AUTOSAR XML (schema 4-2-2)
package /ComponentTypes
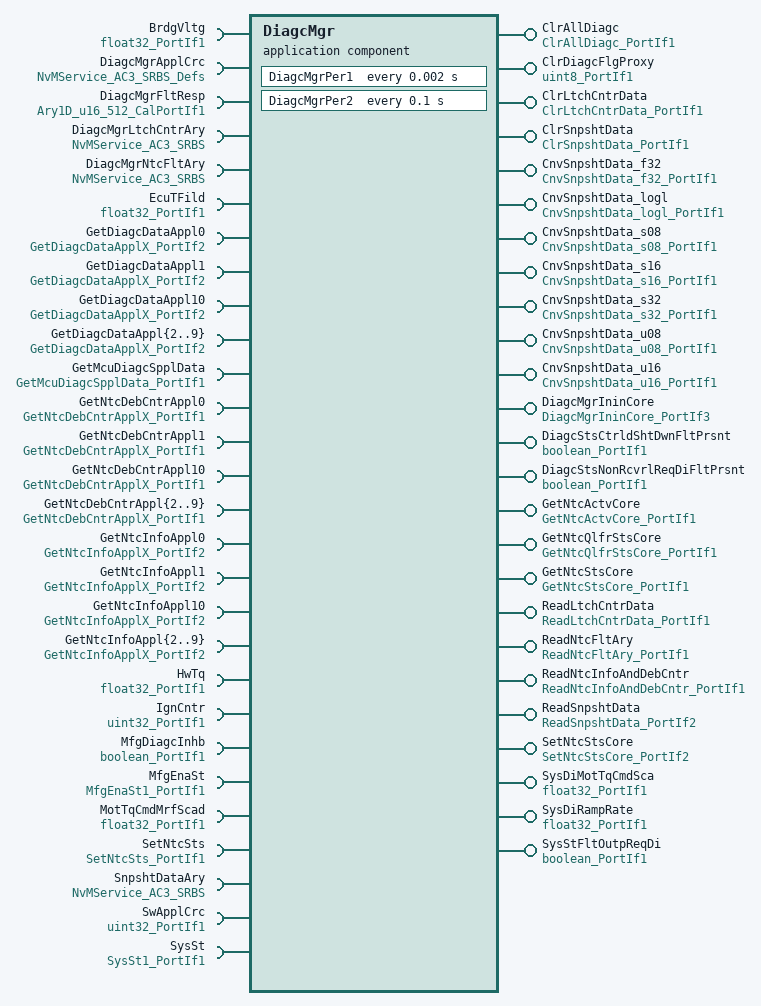
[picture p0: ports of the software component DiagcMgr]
  application sw component type DiagcMgr
    25 x provide port:
      ClrAllDiagc: server-com-spec{operation=Oper, queue-length=1}, provided-interface=ClrAllDiagc_PortIf1
      ClrDiagcFlgProxy: nonqueued-sender-com-spec{data-element=Val, init-value=0}, provided-interface=uint8_PortIf1
      ClrLtchCntrData: server-com-spec{operation=Oper, queue-length=1}, provided-interface=ClrLtchCntrData_PortIf1
      ClrSnpshtData: server-com-spec{operation=Oper, queue-length=1}, provided-interface=ClrSnpshtData_PortIf1
      CnvSnpshtData_f32: server-com-spec{operation=Oper, queue-length=1}, provided-interface=CnvSnpshtData_f32_PortIf1
      CnvSnpshtData_logl: server-com-spec{operation=Oper, queue-length=1}, provided-interface=CnvSnpshtData_logl_PortIf1
      CnvSnpshtData_s08: server-com-spec{operation=Oper, queue-length=1}, provided-interface=CnvSnpshtData_s08_PortIf1
      CnvSnpshtData_s16: server-com-spec{operation=Oper, queue-length=1}, provided-interface=CnvSnpshtData_s16_PortIf1
      CnvSnpshtData_s32: server-com-spec{operation=Oper, queue-length=1}, provided-interface=CnvSnpshtData_s32_PortIf1
      CnvSnpshtData_u08: server-com-spec{operation=Oper, queue-length=1}, provided-interface=CnvSnpshtData_u08_PortIf1
      CnvSnpshtData_u16: server-com-spec{operation=Oper, queue-length=1}, provided-interface=CnvSnpshtData_u16_PortIf1
      DiagcMgrIninCore: server-com-spec{operation=Oper, queue-length=1}, provided-interface=DiagcMgrIninCore_PortIf3
      DiagcStsCtrldShtDwnFltPrsnt: nonqueued-sender-com-spec{data-element=Logl, init-value=0}, provided-interface=boolean_PortIf1
      DiagcStsNonRcvrlReqDiFltPrsnt: nonqueued-sender-com-spec{data-element=Logl, init-value=0}, provided-interface=boolean_PortIf1
      GetNtcActvCore: server-com-spec{operation=Oper, queue-length=1}, provided-interface=GetNtcActvCore_PortIf1
      GetNtcQlfrStsCore: server-com-spec{operation=Oper, queue-length=1}, provided-interface=GetNtcQlfrStsCore_PortIf1
      GetNtcStsCore: server-com-spec{operation=Oper, queue-length=1}, provided-interface=GetNtcStsCore_PortIf1
      ReadLtchCntrData: server-com-spec{operation=Oper, queue-length=1}, provided-interface=ReadLtchCntrData_PortIf1
      ReadNtcFltAry: server-com-spec{operation=Oper, queue-length=1}, provided-interface=ReadNtcFltAry_PortIf1
      ReadNtcInfoAndDebCntr: server-com-spec{operation=Oper, queue-length=1}, provided-interface=ReadNtcInfoAndDebCntr_PortIf1
      ReadSnpshtData: server-com-spec{operation=Oper, queue-length=1}, provided-interface=ReadSnpshtData_PortIf2
      SetNtcStsCore: server-com-spec{operation=Oper, queue-length=1}, provided-interface=SetNtcStsCore_PortIf2
      SysDiMotTqCmdSca: nonqueued-sender-com-spec{data-element=Val, init-value=1}, provided-interface=float32_PortIf1
      SysDiRampRate: nonqueued-sender-com-spec{data-element=Val, init-value=0.1}, provided-interface=float32_PortIf1
      SysStFltOutpReqDi: nonqueued-sender-com-spec{data-element=Logl, init-value=0}, provided-interface=boolean_PortIf1
    49 x require port:
      BrdgVltg: nonqueued-receiver-com-spec{data-element=Val, filter=data-filter-type=ALWAYS, init-value=6}, required-interface=float32_PortIf1
      DiagcMgrApplCrc: required-com-specs=[EraseBlock, GetErrorStatus, InvalidateNvBlock, ReadBlock, RestoreBlockDefaults, SetRamBlockStatus, WriteBlock], required-interface=NvMService_AC3_SRBS_Defs
      DiagcMgrFltResp: parameter-require-com-spec{init-value=[0, 34560, 34560, 34560, 34560, 34560, 34560, 34560, 34560, 34560, 34560, 34560, 34560, 34560, 34560, 34560, 34560, 34560, 34560, 34560, 34560, 34560, 34560, 34560, 34560, 34560, 34560, 34560, 34560, 34560, 34560, 34560, 34560, 34560, 34560, 34560, 34560, 34560, 34560, 34560, 34560, 34560, 34560, 34560, 34560, 34560, 34560, 34560, 34560, 34560, 34560, 34560, 34560, 34560, 34560, 34560, 34560, 34560, 34560, 34560, 34560, 34560, 34560, 34560, 34560, 34560, 34560, 34560, 34560, 34560, 34560, 34560, 34560, 34560, 34560, 34560, 34560, 34560, 34560, 34560, 34560, 34560, 34560, 34560, 34560, 34560, 34560, 34560, 34560, 34560, 34560, 34560, 34560, 34560, 34560, 34560, 34560, 34560, 34560, 34560, 34560, 34560, 34560, 34560, 34560, 34560, 34560, 34560, 34560, 34560, 34560, 34560, 34560, 34560, 34560, 34560, 34560, 34560, 34560, 34560, 34560, 34560, 34560, 34560, 34560, 34560, 34560, 34560, 34560, 34560, 34560, 34560, 34560, 34560, 34560, 34560, 34560, 34560, 34560, 34560, 34560, 34560, 34560, 34560, 34560, 34560, 34560, 34560, 34560, 34560, 34560, 34560, 34560, 34560, 34560, 34560, 34560, 34560, 34560, 34560, 34560, 34560, 34560, 34560, 34560, 34560, 34560, 34560, 34560, 34560, 34560, 34560, 34560, 34560, 34560, 34560, 34560, 34560, 34560, 34560, 34560, 34560, 34560, 34560, 34560, 34560, 34560, 34560, 34560, 34560, 34560, 34560, 34560, 34560, 34560, 34560, 34560, 34560, 34560, 34560, 34560, 34560, 34560, 34560, 34560, 34560, 34560, 34560, 34560, 34560, 34560, 34560, 34560, 34560, 34560, 34560, 34560, 34560, 34560, 34560, 34560, 34560, 34560, 34560, 34560, 34560, 34560, 34560, 34560, 34560, 34560, 34560, 34560, 34560, 34560, 34560, 34560, 34560, 34560, 34560, 34560, 34560, 34560, 34560, 34560, 34560, 34560, 34560, 34560, 34560, 34560, 34560, 34560, 34560, 34560, 34560, 34560, 34560, 34560, 34560, 34560, 34560, 34560, 34560, 34560, 34560, 34560, 34560, 34560, 34560, 34560, 34560, 34560, 34560, 34560, 34560, 34560, 34560, 34560, 34560, 34560, 34560, 34560, 34560, 34560, 34560, 34560, 34560, 34560, 34560, 34560, 34560, 34560, 34560, 34560, 34560, 34560, 34560, 34560, 34560, 34560, 34560, 34560, 34560, 34560, 34560, 34560, 34560, 34560, 34560, 34560, 34560, 34560, 34560, 34560, 34560, 34560, 34560, 34560, 34560, 34560, 34560, 34560, 34560, 34560, 34560, 34560, 34560, 34560, 34560, 34560, 34560, 34560, 34560, 34560, 34560, 34560, 34560, 34560, 34560, 34560, 34560, 34560, 34560, 34560, 34560, 34560, 34560, 34560, 34560, 34560, 34560, 34560, 34560, 34560, 34560, 34560, 34560, 34560, 34560, 34560, 34560, 34560, 34560, 34560, 34560, 34560, 34560, 34560, 34560, 34560, 34560, 34560, 34560, 34560, 34560, 34560, 34560, 34560, 34560, 34560, 34560, 34560, 34560, 34560, 34560, 34560, 34560, 34560, 34560, 34560, 34560, 34560, 34560, 34560, 34560, 34560, 34560, 34560, 34560, 34560, 34560, 34560, 34560, 34560, 34560, 34560, 34560, 34560, 34560, 34560, 34560, 34560, 34560, 34560, 34560, 34560, 34560, 34560, 34560, 34560, 34560, 34560, 34560, 34560, 34560, 34560, 34560, 34560, 34560, 34560, 34560, 34560, 34560, 34560, 34560, 34560, 34560, 34560, 34560, 34560, 34560, 34560, 34560, 34560, 34560, 34560, 34560, 34560, 34560, 34560, 34560, 34560, 34560, 34560, 34560, 34560, 34560, 34560, 34560, 34560, 34560, 34560, 34560, 34560, 34560, 34560, 34560, 34560, 34560, 34560, 34560, 34560, 34560, 34560, 34560, 34560, 34560, 34560, 34560, 34560, 34560, 34560, 34560, 34560, 34560, 34560, 34560, 34560, 34560, 34560, 34560, 34560, 34560, 34560, 34560, 34560, 34560, 34560, 34560, 34560, 34560, 34560, 34560, 34560, 34560, 34560, 34560, 34560, 34560, 34560, 34560], parameter=Ary1D}, required-interface=Ary1D_u16_512_CalPortIf1
      DiagcMgrLtchCntrAry: required-com-specs=[EraseBlock, GetErrorStatus, InvalidateNvBlock, ReadBlock, SetRamBlockStatus, WriteBlock], required-interface=NvMService_AC3_SRBS
      DiagcMgrNtcFltAry: required-com-specs=[EraseBlock, GetErrorStatus, InvalidateNvBlock, ReadBlock, SetRamBlockStatus, WriteBlock], required-interface=NvMService_AC3_SRBS
      EcuTFild: nonqueued-receiver-com-spec{data-element=Val, filter=data-filter-type=ALWAYS, init-value=25}, required-interface=float32_PortIf1
      GetDiagcDataAppl0: client-com-spec=Oper, required-interface=GetDiagcDataApplX_PortIf2
      GetDiagcDataAppl1: client-com-spec=Oper, required-interface=GetDiagcDataApplX_PortIf2
      GetDiagcDataAppl10: client-com-spec=Oper, required-interface=GetDiagcDataApplX_PortIf2
      GetDiagcDataAppl{2..9}: client-com-spec=Oper, required-interface=GetDiagcDataApplX_PortIf2
      GetMcuDiagcSpplData: client-com-spec=Oper, required-interface=GetMcuDiagcSpplData_PortIf1
      GetNtcDebCntrAppl0: client-com-spec=Oper, required-interface=GetNtcDebCntrApplX_PortIf1
      GetNtcDebCntrAppl1: client-com-spec=Oper, required-interface=GetNtcDebCntrApplX_PortIf1
      GetNtcDebCntrAppl10: client-com-spec=Oper, required-interface=GetNtcDebCntrApplX_PortIf1
      GetNtcDebCntrAppl{2..9}: client-com-spec=Oper, required-interface=GetNtcDebCntrApplX_PortIf1
      GetNtcInfoAppl0: client-com-spec=Oper, required-interface=GetNtcInfoApplX_PortIf2
      GetNtcInfoAppl1: client-com-spec=Oper, required-interface=GetNtcInfoApplX_PortIf2
      GetNtcInfoAppl10: client-com-spec=Oper, required-interface=GetNtcInfoApplX_PortIf2
      GetNtcInfoAppl{2..9}: client-com-spec=Oper, required-interface=GetNtcInfoApplX_PortIf2
      HwTq: nonqueued-receiver-com-spec{data-element=Val, filter=data-filter-type=ALWAYS, init-value=0}, required-interface=float32_PortIf1
      IgnCntr: nonqueued-receiver-com-spec{data-element=Val, filter=data-filter-type=ALWAYS, init-value=0}, required-interface=uint32_PortIf1
      MfgDiagcInhb: nonqueued-receiver-com-spec{data-element=Logl, filter=data-filter-type=ALWAYS, init-value=0}, required-interface=boolean_PortIf1
      MfgEnaSt: nonqueued-receiver-com-spec{data-element=Val, filter=data-filter-type=ALWAYS, init-value=0}, required-interface=MfgEnaSt1_PortIf1
      MotTqCmdMrfScad: nonqueued-receiver-com-spec{data-element=Val, filter=data-filter-type=ALWAYS, init-value=0}, required-interface=float32_PortIf1
      SetNtcSts: client-com-spec=Oper, required-interface=SetNtcSts_PortIf1
      SnpshtDataAry: required-com-specs=[EraseBlock, GetErrorStatus, InvalidateNvBlock, ReadBlock, SetRamBlockStatus, WriteBlock], required-interface=NvMService_AC3_SRBS
      SwApplCrc: nonqueued-receiver-com-spec{data-element=Val, filter=data-filter-type=ALWAYS, init-value=0}, required-interface=uint32_PortIf1
      SysSt: nonqueued-receiver-com-spec{data-element=Val, filter=data-filter-type=ALWAYS, init-value=3}, required-interface=SysSt1_PortIf1
    behavior DiagcMgr_InternalBehavior
      exclusive area DiagcMgrExclusiveArea
      ar-typed-per-instance-memorys:
        7 x data:
          ClrDiagcFlg: sw-calibration-access=READ-ONLY, type=uint8
          DiagcMgrApplCrc: sw-calibration-access=READ-ONLY, type=uint32
          DiagcMgrLtchCntrAry: sw-calibration-access=READ-ONLY, type=Ary1D_u08_20
          DiagcMgrNtcFltAry: sw-calibration-access=READ-ONLY, type=Ary1D_NtcFltInfoRec2_20
          DtcEnaSts: sw-calibration-access=READ-ONLY, type=uint16
          DtcIdxPrevSts: type=Ary1D_u08_DiagcMgr1
          PrevClrDtcFlg: sw-calibration-access=READ-ONLY, type=uint8
      11 x operation invoked event:
        OIT_ClrAllDiagc_Oper_ClrAllDiagc_Oper: start-on-event=ClrAllDiagc_Oper, operation=ClrAllDiagc.Oper
        OIT_ClrLtchCntrData_Oper_ClrLtchCntrData_Oper: start-on-event=ClrLtchCntrData_Oper, operation=ClrLtchCntrData.Oper
        OIT_ClrSnpshtData_Oper_ClrSnpshtData_Oper: start-on-event=ClrSnpshtData_Oper, operation=ClrSnpshtData.Oper
        OIT_CnvSnpshtData_f32_Oper_CnvSnpshtData_f32_Oper: start-on-event=CnvSnpshtData_f32_Oper, operation=CnvSnpshtData_f32.Oper
        OIT_CnvSnpshtData_logl_Oper_CnvSnpshtData_logl_Oper: start-on-event=CnvSnpshtData_logl_Oper, operation=CnvSnpshtData_logl.Oper
        OIT_CnvSnpshtData_s08_Oper_CnvSnpshtData_s08_Oper: start-on-event=CnvSnpshtData_s08_Oper, operation=CnvSnpshtData_s08.Oper
        OIT_CnvSnpshtData_s16_Oper_CnvSnpshtData_s16_Oper: start-on-event=CnvSnpshtData_s16_Oper, operation=CnvSnpshtData_s16.Oper
        OIT_CnvSnpshtData_s32_Oper_CnvSnpshtData_s32_Oper: start-on-event=CnvSnpshtData_s32_Oper, operation=CnvSnpshtData_s32.Oper
        OIT_CnvSnpshtData_u08_Oper_CnvSnpshtData_u08_Oper: start-on-event=CnvSnpshtData_u08_Oper, operation=CnvSnpshtData_u08.Oper
        OIT_CnvSnpshtData_u16_Oper_CnvSnpshtData_u16_Oper: start-on-event=CnvSnpshtData_u16_Oper, operation=CnvSnpshtData_u16.Oper
        OIT_DiagcMgrIninCore_Oper_DiagcMgrIninCore_Oper: start-on-event=DiagcMgrIninCore_Oper, operation=DiagcMgrIninCore.Oper
      init event DiagcMgr_InitEvent: start-on-event=DiagcMgrInit1
      timing event TMT_DiagcMgrPer1: start-on-event=DiagcMgrPer1, period=0.002
      timing event TMT_DiagcMgrPer2: start-on-event=DiagcMgrPer2, period=0.1
      8 x operation invoked event:
        OIT_GetNtcActvCore_Oper_GetNtcActvCore_Oper: start-on-event=GetNtcActvCore_Oper, operation=GetNtcActvCore.Oper
        OIT_GetNtcQlfrStsCore_Oper_GetNtcQlfrStsCore_Oper: start-on-event=GetNtcQlfrStsCore_Oper, operation=GetNtcQlfrStsCore.Oper
        OIT_GetNtcStsCore_Oper_GetNtcStsCore_Oper: start-on-event=GetNtcStsCore_Oper, operation=GetNtcStsCore.Oper
        OIT_ReadLtchCntrData_Oper_ReadLtchCntrData_Oper: start-on-event=ReadLtchCntrData_Oper, operation=ReadLtchCntrData.Oper
        OIT_ReadNtcFltAry_Oper_ReadNtcFltAry_Oper: start-on-event=ReadNtcFltAry_Oper, operation=ReadNtcFltAry.Oper
        OIT_ReadNtcInfoAndDebCntr_Oper_ReadNtcInfoAndDebCntr_Oper: start-on-event=ReadNtcInfoAndDebCntr_Oper, operation=ReadNtcInfoAndDebCntr.Oper
        OIT_ReadSnpshtData_Oper_ReadSnpshtData_Oper: start-on-event=ReadSnpshtData_Oper, operation=ReadSnpshtData.Oper
        OIT_SetNtcStsCore_Oper_SetNtcStsCore_Oper: start-on-event=SetNtcStsCore_Oper, operation=SetNtcStsCore.Oper
      22 x runnable:
        ClrAllDiagc_Oper: can-be-invoked-concurrently=true
          data-send-points:
            access SEND_ClrDiagcFlg_Val: accessed-variable=ClrDiagcFlgProxy.Val
        ClrLtchCntrData_Oper
          sync call SC_DiagcMgrLtchCntrAry_SetRamBlockStatus: operation=DiagcMgrLtchCntrAry.SetRamBlockStatus, timeout=0
        ClrSnpshtData_Oper
          sync call SC_SnpshtDataAry_SetRamBlockStatus: operation=SnpshtDataAry.SetRamBlockStatus, timeout=0
        CnvSnpshtData_f32_Oper: can-be-invoked-concurrently=true
        CnvSnpshtData_logl_Oper: can-be-invoked-concurrently=true
        CnvSnpshtData_s08_Oper: can-be-invoked-concurrently=true
        CnvSnpshtData_s16_Oper: can-be-invoked-concurrently=true
        CnvSnpshtData_s32_Oper: can-be-invoked-concurrently=true
        CnvSnpshtData_u08_Oper: can-be-invoked-concurrently=true
        CnvSnpshtData_u16_Oper: can-be-invoked-concurrently=true
        DiagcMgrIninCore_Oper: can-be-invoked-concurrently=true
        DiagcMgrInit1
          data-receive-point-by-arguments:
            access REC_SwApplCrc_Val: accessed-variable=SwApplCrc.Val
          sync call SC_DiagcMgrApplCrc_SetRamBlockStatus: operation=DiagcMgrApplCrc.SetRamBlockStatus, timeout=0
          sync call SC_SetNtcSts_Oper: operation=SetNtcSts.Oper, timeout=0
        DiagcMgrPer1
          data-send-points:
            5 x access:
              SEND_DiagcStsCtrldShtDwnFltPrsnt_Logl: accessed-variable=DiagcStsCtrldShtDwnFltPrsnt.Logl
              SEND_DiagcStsNonRcvrlReqDiFltPrsnt_Logl: accessed-variable=DiagcStsNonRcvrlReqDiFltPrsnt.Logl
              SEND_SysDiMotTqCmdSca_Val: accessed-variable=SysDiMotTqCmdSca.Val
              SEND_SysDiRampRate_Val: accessed-variable=SysDiRampRate.Val
              SEND_SysStFltOutpReqDi_Logl: accessed-variable=SysStFltOutpReqDi.Logl
          11 x sync call, all with timeout=0:
            SC_GetDiagcDataAppl0_Oper: operation=GetDiagcDataAppl0.Oper
            SC_GetDiagcDataAppl1_Oper: operation=GetDiagcDataAppl1.Oper
            SC_GetDiagcDataAppl10_Oper: operation=GetDiagcDataAppl10.Oper
            SC_GetDiagcDataAppl{2..9}_Oper: operation=GetDiagcDataAppl{2..9}.Oper
        DiagcMgrPer2
          11 x sync call, all with timeout=0:
            SC_GetNtcInfoAppl0_Oper: operation=GetNtcInfoAppl0.Oper
            SC_GetNtcInfoAppl1_Oper: operation=GetNtcInfoAppl1.Oper
            SC_GetNtcInfoAppl10_Oper: operation=GetNtcInfoAppl10.Oper
            SC_GetNtcInfoAppl{2..9}_Oper: operation=GetNtcInfoAppl{2..9}.Oper
        GetNtcActvCore_Oper: can-be-invoked-concurrently=true
          11 x sync call, all with timeout=0:
            SC_GetNtcInfoAppl0_Oper: operation=GetNtcInfoAppl0.Oper
            SC_GetNtcInfoAppl1_Oper: operation=GetNtcInfoAppl1.Oper
            SC_GetNtcInfoAppl10_Oper: operation=GetNtcInfoAppl10.Oper
            SC_GetNtcInfoAppl{2..9}_Oper: operation=GetNtcInfoAppl{2..9}.Oper
        GetNtcQlfrStsCore_Oper: can-be-invoked-concurrently=true
          11 x sync call, all with timeout=0:
            SC_GetNtcInfoAppl0_Oper: operation=GetNtcInfoAppl0.Oper
            SC_GetNtcInfoAppl1_Oper: operation=GetNtcInfoAppl1.Oper
            SC_GetNtcInfoAppl10_Oper: operation=GetNtcInfoAppl10.Oper
            SC_GetNtcInfoAppl{2..9}_Oper: operation=GetNtcInfoAppl{2..9}.Oper
        GetNtcStsCore_Oper: can-be-invoked-concurrently=true
          11 x sync call, all with timeout=0:
            SC_GetNtcInfoAppl0_Oper: operation=GetNtcInfoAppl0.Oper
            SC_GetNtcInfoAppl1_Oper: operation=GetNtcInfoAppl1.Oper
            SC_GetNtcInfoAppl10_Oper: operation=GetNtcInfoAppl10.Oper
            SC_GetNtcInfoAppl{2..9}_Oper: operation=GetNtcInfoAppl{2..9}.Oper
        ReadLtchCntrData_Oper
        ReadNtcFltAry_Oper: can-be-invoked-concurrently=true
          11 x sync call, all with timeout=0:
            SC_GetNtcInfoAppl0_Oper: operation=GetNtcInfoAppl0.Oper
            SC_GetNtcInfoAppl1_Oper: operation=GetNtcInfoAppl1.Oper
            SC_GetNtcInfoAppl10_Oper: operation=GetNtcInfoAppl10.Oper
            SC_GetNtcInfoAppl{2..9}_Oper: operation=GetNtcInfoAppl{2..9}.Oper
        ReadNtcInfoAndDebCntr_Oper: can-be-invoked-concurrently=true
          22 x sync call, all with timeout=0:
            SC_GetNtcDebCntrAppl0_Oper: operation=GetNtcDebCntrAppl0.Oper
            SC_GetNtcDebCntrAppl1_Oper: operation=GetNtcDebCntrAppl1.Oper
            SC_GetNtcDebCntrAppl10_Oper: operation=GetNtcDebCntrAppl10.Oper
            SC_GetNtcDebCntrAppl{2..9}_Oper: operation=GetNtcDebCntrAppl{2..9}.Oper
            SC_GetNtcInfoAppl0_Oper: operation=GetNtcInfoAppl0.Oper
            SC_GetNtcInfoAppl1_Oper: operation=GetNtcInfoAppl1.Oper
            SC_GetNtcInfoAppl10_Oper: operation=GetNtcInfoAppl10.Oper
            SC_GetNtcInfoAppl{2..9}_Oper: operation=GetNtcInfoAppl{2..9}.Oper
        ReadSnpshtData_Oper
        SetNtcStsCore_Oper: can-enter-exclusive-area=DiagcMgrExclusiveArea, can-be-invoked-concurrently=true
          data-receive-point-by-arguments:
            8 x access:
              REC_BrdgVltg_Val: accessed-variable=BrdgVltg.Val
              REC_EcuTFild_Val: accessed-variable=EcuTFild.Val
              REC_Hwtq_Val: accessed-variable=HwTq.Val
              REC_IgnCntr_Val_1: accessed-variable=IgnCntr.Val
              REC_MfgDiagcInhb_Logl: accessed-variable=MfgDiagcInhb.Logl
              REC_MfgEnaSt_Val: accessed-variable=MfgEnaSt.Val
              REC_MotTqCmdMrfScad_Val: accessed-variable=MotTqCmdMrfScad.Val
              REC_SysSt_Val: accessed-variable=SysSt.Val
          sync call SC_GetMcuDiagcSpplData_Oper: operation=GetMcuDiagcSpplData.Oper, timeout=0
          sync call SC_SnpshtDataAry_SetRamBlockStatus: operation=SnpshtDataAry.SetRamBlockStatus, timeout=0
      swc service dependency NvMDiagcMgrApplCrc: assigned-ports=role-based-port-assignment={port-prototype=DiagcMgrApplCrc, role=NvMService_AC3_SRBS_Defs}
        assigned-datas:
          role=ramBlock, used-data-element=DiagcMgrApplCrc
          role=defaultValue, used-parameter-element=DiagcMgrApplCrcDft
        service-needs:
          nv block needs NvMDiagcMgrApplCrc: n-data-sets=0, ram-block-status-control=API, readonly=false, reliability=ERROR-DETECTION, resistant-to-changed-sw=true, restore-at-start=true, store-at-shutdown=true, write-only-once=false, writing-frequency=0, writing-priority=LOW
      swc service dependency NvmDiagcMgrLtchCntrAry: assigned-datas=role-based-data-assignment={role=ramBlock, used-data-element=DiagcMgrLtchCntrAry}, assigned-ports=role-based-port-assignment={port-prototype=DiagcMgrLtchCntrAry, role=NvMService_AC3_SRBS}
        service-needs:
          nv block needs NvmDiagcMgrLtchCntrAry: n-data-sets=0, ram-block-status-control=API, readonly=false, reliability=ERROR-DETECTION, resistant-to-changed-sw=true, restore-at-start=true, store-at-shutdown=true, write-only-once=false, writing-frequency=0, writing-priority=LOW
      swc service dependency NvmDiagcMgrNtcFltAry: assigned-datas=role-based-data-assignment={role=ramBlock, used-data-element=DiagcMgrNtcFltAry}, assigned-ports=role-based-port-assignment={port-prototype=DiagcMgrNtcFltAry, role=NvMService_AC3_SRBS}
        service-needs:
          nv block needs NvmDiagcMgrNtcFltAry: n-data-sets=0, ram-block-status-control=API, readonly=false, reliability=ERROR-DETECTION, resistant-to-changed-sw=true, restore-at-start=true, store-at-shutdown=true, write-only-once=false, writing-frequency=0, writing-priority=LOW
      shared-parameters:
        parameter data prototype DiagcMgrApplCrcDft: sw-calibration-access=READ-WRITE, type=uint32, init-value=0
  swc implementation DiagcMgr_Implementation: behavior=DiagcMgr_InternalBehavior
    code-descriptors:
      code Default: artifact-descriptors=autosar-engineering-object={short-label=Default, category=SWSRC}
